VERSION ""

NS_ :

BS_:

BU_: EMS EPB TCU

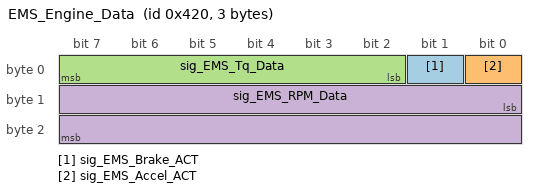
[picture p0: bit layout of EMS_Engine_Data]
BO_ 1056 EMS_Engine_Data: 3 EMS
 SG_ sig_EMS_Brake_ACT : 1|1@1+ (1,0) [0|1] "" Vector__XXX
 SG_ sig_EMS_Accel_ACT : 0|1@1+ (1,0) [0|1] "" Vector__XXX
 SG_ sig_EMS_Tq_Data : 2|6@1+ (10,0) [0|630] "Nm" Vector__XXX
 SG_ sig_EMS_RPM_Data : 8|16@1+ (0.25,0) [0|16383.75] "rpm" Vector__XXX

BO_ 1041 EPB_Press_data: 2 EPB
 SG_ sig_EPB_CylinderPress : 1|12@1+ (0.1,0) [0|409.5] "Bar" Vector__XXX
 SG_ sig_EPB_CylinderState : 0|1@1+ (1,0) [0|1] "" Vector__XXX

BO_ 1040 EPB_State_Data: 1 EPB
 SG_ sig_EPB_ACT : 1|1@1+ (1,0) [0|1] "" Vector__XXX
 SG_ sig_EPB_State : 0|1@1+ (1,0) [0|1] "" Vector__XXX

BO_ 1024 TCU_Gear_Data: 1 TCU
 SG_ sig_TCU_GearState : 0|1@1+ (1,0) [0|1] "" Vector__XXX
 SG_ sig_TCU_GearType : 1|4@1+ (1,0) [0|15] "" Vector__XXX

BA_DEF_  "BusType" STRING ;
BA_DEF_DEF_  "BusType" "CAN";
